# PIC32MM0256GPM036 register map
Vendor: Microchip
Registers are 32-bit, read-write, reset 0x0 unless marked. A register's access mark holds for its fields unless they carry their own. Addresses are absolute, and some are shared; only a register's first bit layout is shown; [hi:lo] are bit positions.

## CCP4
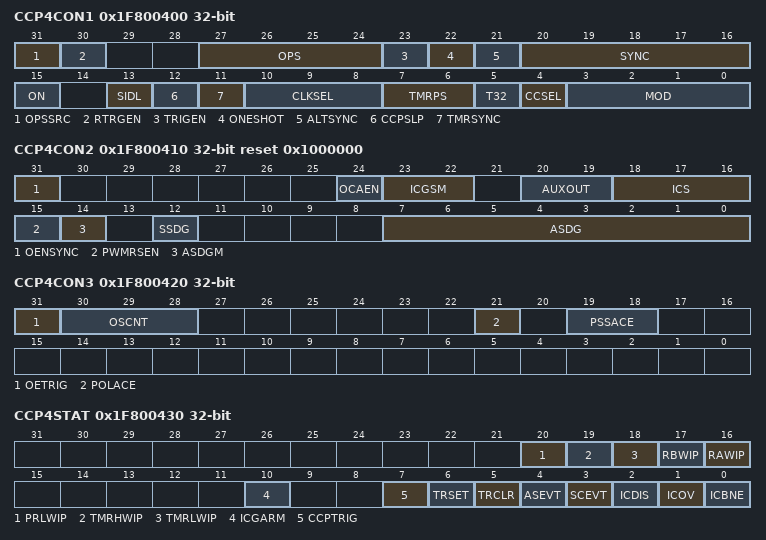
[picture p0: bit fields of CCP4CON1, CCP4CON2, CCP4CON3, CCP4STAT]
0x1F800400 CCP4CON1
  [31] OPSSRC, [30] RTRGEN, [27:24] OPS, [23] TRIGEN, [22] ONESHOT, [21] ALTSYNC, [20:16] SYNC, [15] ON, [13] SIDL, [12] CCPSLP, [11] TMRSYNC, [10:8] CLKSEL, [7:6] TMRPS, [5] T32, [4] CCSEL, [3:0] MOD
0x1F800410 CCP4CON2 reset 0x1000000
  [31] OENSYNC, [24] OCAEN, [23:22] ICGSM, [20:19] AUXOUT, [18:16] ICS, [15] PWMRSEN, [14] ASDGM, [12] SSDG, [7:0] ASDG
0x1F800420 CCP4CON3
  [31] OETRIG, [30:28] OSCNT, [21] POLACE, [19:18] PSSACE
0x1F800430 CCP4STAT
  [20] PRLWIP
  [19] TMRHWIP
  [18] TMRLWIP
  [17] RBWIP
  [16] RAWIP
  [10] ICGARM
  [7] CCPTRIG ro
  [6] TRSET
  [5] TRCLR
  [4] ASEVT — (can only be cleared)
  [3] SCEVT — (can only be cleared)
  [2] ICDIS ro
  [1] ICOV — (can only be cleared)
  [0] ICBNE ro
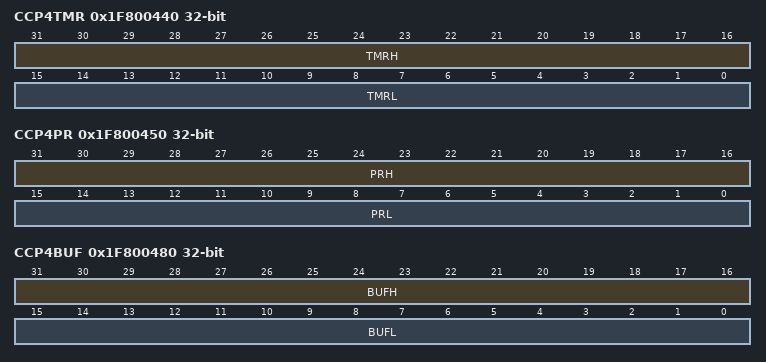
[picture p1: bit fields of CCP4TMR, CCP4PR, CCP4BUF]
0x1F800440 CCP4TMR
  [31:16] TMRH, [15:0] TMRL
0x1F800450 CCP4PR
  [31:16] PRH, [15:0] PRL
0x1F800460 CCP4RA
  [15:0] CMPA
0x1F800470 CCP4RB
  [15:0] CMPB
0x1F800480 CCP4BUF
  [31:16] BUFH, [15:0] BUFL

## CCP5
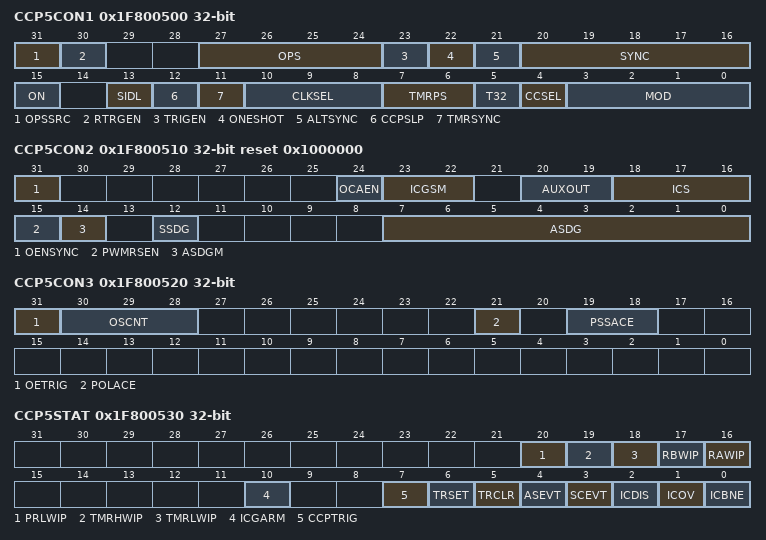
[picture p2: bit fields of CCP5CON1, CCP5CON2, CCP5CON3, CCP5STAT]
0x1F800500 CCP5CON1
  [31] OPSSRC, [30] RTRGEN, [27:24] OPS, [23] TRIGEN, [22] ONESHOT, [21] ALTSYNC, [20:16] SYNC, [15] ON, [13] SIDL, [12] CCPSLP, [11] TMRSYNC, [10:8] CLKSEL, [7:6] TMRPS, [5] T32, [4] CCSEL, [3:0] MOD
0x1F800510 CCP5CON2 reset 0x1000000
  [31] OENSYNC, [24] OCAEN, [23:22] ICGSM, [20:19] AUXOUT, [18:16] ICS, [15] PWMRSEN, [14] ASDGM, [12] SSDG, [7:0] ASDG
0x1F800520 CCP5CON3
  [31] OETRIG, [30:28] OSCNT, [21] POLACE, [19:18] PSSACE
0x1F800530 CCP5STAT
  [20] PRLWIP
  [19] TMRHWIP
  [18] TMRLWIP
  [17] RBWIP
  [16] RAWIP
  [10] ICGARM
  [7] CCPTRIG ro
  [6] TRSET
  [5] TRCLR
  [4] ASEVT — (can only be cleared)
  [3] SCEVT — (can only be cleared)
  [2] ICDIS ro
  [1] ICOV — (can only be cleared)
  [0] ICBNE ro
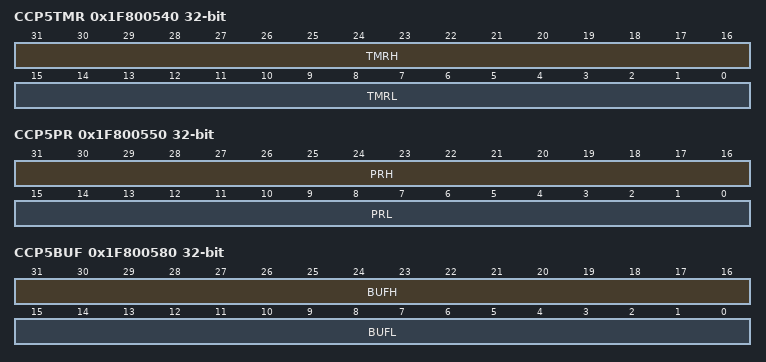
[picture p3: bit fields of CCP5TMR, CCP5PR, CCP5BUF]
0x1F800540 CCP5TMR
  [31:16] TMRH, [15:0] TMRL
0x1F800550 CCP5PR
  [31:16] PRH, [15:0] PRL
0x1F800560 CCP5RA
  [15:0] CMPA
0x1F800570 CCP5RB
  [15:0] CMPB
0x1F800580 CCP5BUF
  [31:16] BUFH, [15:0] BUFL

## CCP6
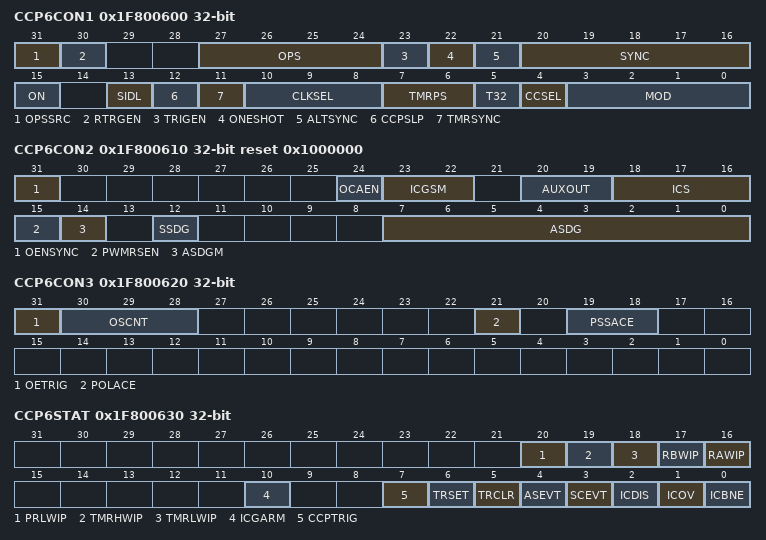
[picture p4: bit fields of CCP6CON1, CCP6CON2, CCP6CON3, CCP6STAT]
0x1F800600 CCP6CON1
  [31] OPSSRC, [30] RTRGEN, [27:24] OPS, [23] TRIGEN, [22] ONESHOT, [21] ALTSYNC, [20:16] SYNC, [15] ON, [13] SIDL, [12] CCPSLP, [11] TMRSYNC, [10:8] CLKSEL, [7:6] TMRPS, [5] T32, [4] CCSEL, [3:0] MOD
0x1F800610 CCP6CON2 reset 0x1000000
  [31] OENSYNC, [24] OCAEN, [23:22] ICGSM, [20:19] AUXOUT, [18:16] ICS, [15] PWMRSEN, [14] ASDGM, [12] SSDG, [7:0] ASDG
0x1F800620 CCP6CON3
  [31] OETRIG, [30:28] OSCNT, [21] POLACE, [19:18] PSSACE
0x1F800630 CCP6STAT
  [20] PRLWIP
  [19] TMRHWIP
  [18] TMRLWIP
  [17] RBWIP
  [16] RAWIP
  [10] ICGARM
  [7] CCPTRIG ro
  [6] TRSET
  [5] TRCLR
  [4] ASEVT — (can only be cleared)
  [3] SCEVT — (can only be cleared)
  [2] ICDIS ro
  [1] ICOV — (can only be cleared)
  [0] ICBNE ro
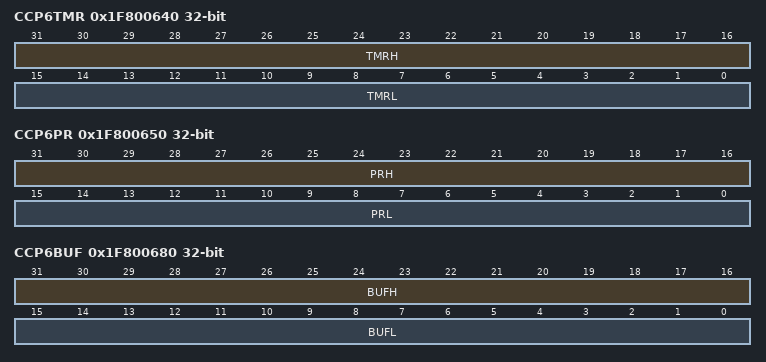
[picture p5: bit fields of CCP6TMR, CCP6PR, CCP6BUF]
0x1F800640 CCP6TMR
  [31:16] TMRH, [15:0] TMRL
0x1F800650 CCP6PR
  [31:16] PRH, [15:0] PRL
0x1F800660 CCP6RA
  [15:0] CMPA
0x1F800670 CCP6RB
  [15:0] CMPB
0x1F800680 CCP6BUF
  [31:16] BUFH, [15:0] BUFL

## CCP7
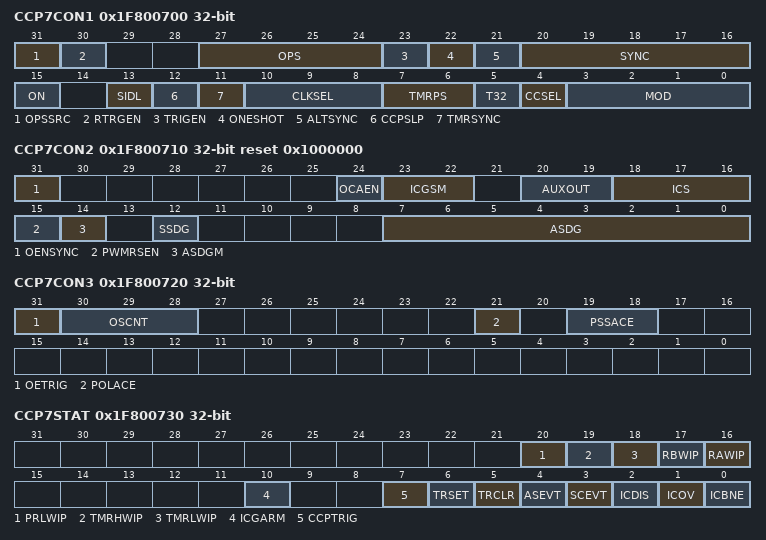
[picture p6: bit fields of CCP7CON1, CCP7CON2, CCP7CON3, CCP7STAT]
0x1F800700 CCP7CON1
  [31] OPSSRC, [30] RTRGEN, [27:24] OPS, [23] TRIGEN, [22] ONESHOT, [21] ALTSYNC, [20:16] SYNC, [15] ON, [13] SIDL, [12] CCPSLP, [11] TMRSYNC, [10:8] CLKSEL, [7:6] TMRPS, [5] T32, [4] CCSEL, [3:0] MOD
0x1F800710 CCP7CON2 reset 0x1000000
  [31] OENSYNC, [24] OCAEN, [23:22] ICGSM, [20:19] AUXOUT, [18:16] ICS, [15] PWMRSEN, [14] ASDGM, [12] SSDG, [7:0] ASDG
0x1F800720 CCP7CON3
  [31] OETRIG, [30:28] OSCNT, [21] POLACE, [19:18] PSSACE
0x1F800730 CCP7STAT
  [20] PRLWIP
  [19] TMRHWIP
  [18] TMRLWIP
  [17] RBWIP
  [16] RAWIP
  [10] ICGARM
  [7] CCPTRIG ro
  [6] TRSET
  [5] TRCLR
  [4] ASEVT — (can only be cleared)
  [3] SCEVT — (can only be cleared)
  [2] ICDIS ro
  [1] ICOV — (can only be cleared)
  [0] ICBNE ro
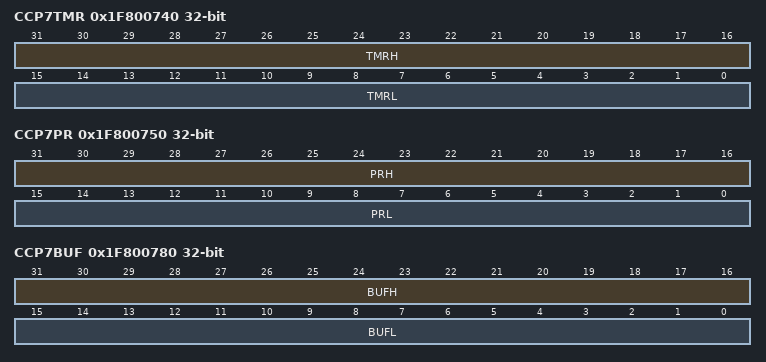
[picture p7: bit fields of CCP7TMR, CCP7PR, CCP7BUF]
0x1F800740 CCP7TMR
  [31:16] TMRH, [15:0] TMRL
0x1F800750 CCP7PR
  [31:16] PRH, [15:0] PRL
0x1F800760 CCP7RA
  [15:0] CMPA
0x1F800770 CCP7RB
  [15:0] CMPB
0x1F800780 CCP7BUF
  [31:16] BUFH, [15:0] BUFL
